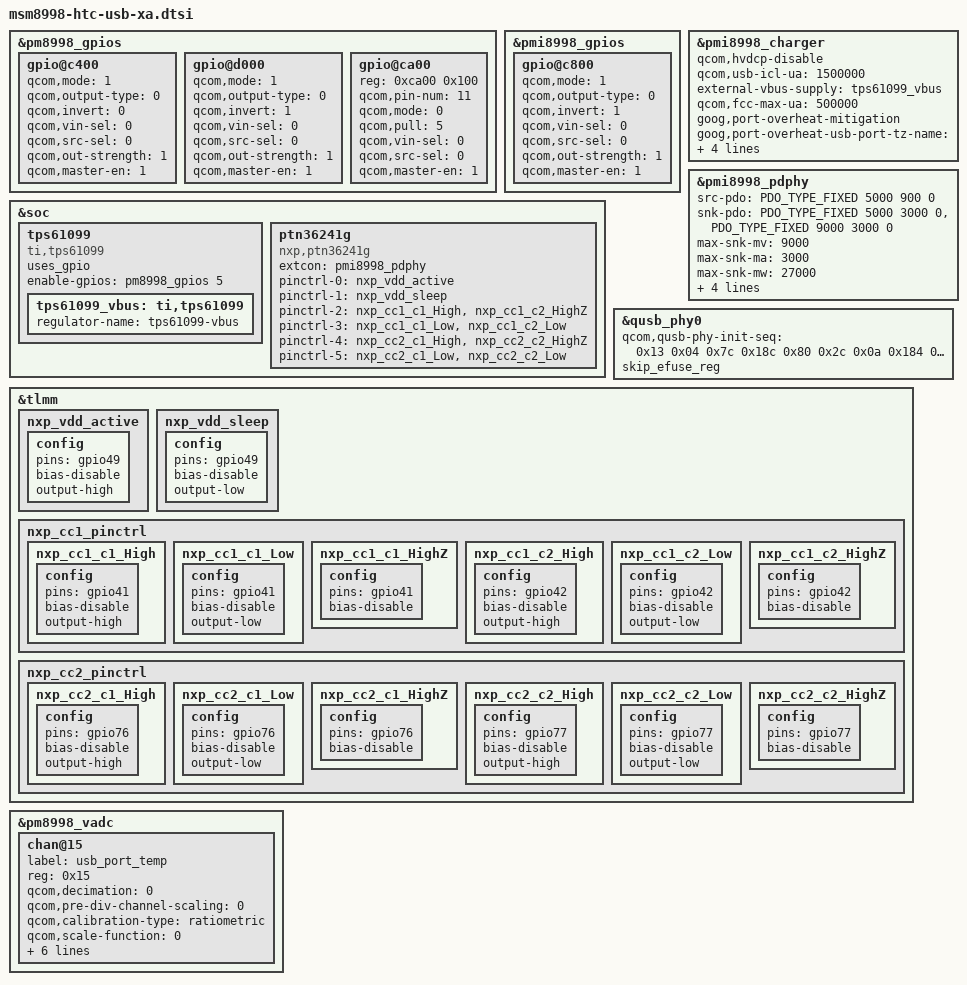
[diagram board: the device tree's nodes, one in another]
/*
 * Copyright (c) 2017, The Linux Foundation. All rights reserved.
 *
 * This program is free software; you can redistribute it and/or modify
 * it under the terms of the GNU General Public License version 2 and
 * only version 2 as published by the Free Software Foundation.
 *
 * This program is distributed in the hope that it will be useful,
 * but WITHOUT ANY WARRANTY; without even the implied warranty of
 * MERCHANTABILITY or FITNESS FOR A PARTICULAR PURPOSE.  See the
 * GNU General Public License for more details.
 */

#include <dt-bindings/usb/typec.h>

&pm8998_gpios {
	gpio@c400 { /* GPIO 5 - V_OTG_5V_EN_AP */
		qcom,mode = <1>;
		qcom,output-type = <0>;
		qcom,invert = <0>;
		qcom,vin-sel = <0>;
		qcom,src-sel = <0>;
		qcom,out-strength = <1>;
		qcom,master-en = <1>;
		status = "okay";
	};

	gpio@d000 { /* GPIO 17 - V_OTG_VOUT_SET */
		qcom,mode = <1>;
		qcom,output-type = <0>;
		qcom,invert = <1>;
		qcom,vin-sel = <0>;
		qcom,src-sel = <0>;
		qcom,out-strength = <1>;
		qcom,master-en = <1>;
		status = "okay";
	};
};

&pmi8998_gpios {
	gpio@c800 { /* GPIO 9 - V_LED_3V3_EN - shared power for Re-drive */
		qcom,mode = <1>;
		qcom,output-type = <0>;
		qcom,invert = <1>;
		qcom,vin-sel = <0>;
		qcom,src-sel = <0>;
		qcom,out-strength = <1>;
		qcom,master-en = <1>;
		status = "okay";
	};
};

&soc {
	tps61099 {
		compatible = "ti,tps61099";
		uses_gpio;

		enable-gpios = <&pm8998_gpios 5 0>;

		tps61099_vbus: ti,tps61099 {
			regulator-name = "tps61099-vbus";
		};
	};
};

&pmi8998_charger {
	qcom,hvdcp-disable;		/* disable HVDCP */
	qcom,usb-icl-ua = <1500000>;
	external-vbus-supply = <&tps61099_vbus>;
	/*
	 * a conservative value used to limit charge current in case the
	 * charging module is not loaded. The charging module would change
	 * the value to allow faster charging.
	 */
	qcom,fcc-max-ua = <500000>;
};

&pmi8998_pdphy {
	src-pdo = <PDO_TYPE_FIXED 5000 900 0>;	/* 5V-0.9A */
	snk-pdo = <PDO_TYPE_FIXED 5000 3000 0>,	/* 5V-3A */
		  <PDO_TYPE_FIXED 9000 3000 0>;	/* 9V-3A */
	max-snk-mv = <9000>;
	max-snk-ma = <3000>;
	max-snk-mw = <27000>;
	op-snk-mw = <7600>;
	port-type = <TYPEC_PORT_DRP>;
	default-role = <TYPEC_SINK>;
	try-role-hw;
};

&qusb_phy0 {
	qcom,qusb-phy-init-seq =
			/* <value reg_offset> */
				<0x13 0x04 /* analog_controls_two */
				0x7c 0x18c /* pll_clock_inverter */
				0x80 0x2c /* pll_cmode */
				0x0a 0x184 /* pll_lock_delay */
				0xf5 0x23c /* tune1 */
				0x0b 0x240 /* tune2 */
				0xe4 0x248 /* tune4 */
				0x19 0xb4>; /* digital_timers_two */
	skip_efuse_reg;
};

&soc {
	ptn36241g {
		compatible = "nxp,ptn36241g";
		extcon = <&pmi8998_pdphy>;

		pinctrl-names = "nxp_vdd_active", "nxp_vdd_sleep",
				"nxp_cc1_active-HH", "nxp_cc1_sleep-LL",
				"nxp_cc2_active-HH", "nxp_cc2_sleep-LL";
		/*USBSS_SW_1V8_EN - on*/
		pinctrl-0 = <&nxp_vdd_active>;
		/*USBSS_SW_1V8_EN - off*/
		pinctrl-1 = <&nxp_vdd_sleep>;
		/*nxp_cc1_active-HH*/
		pinctrl-2 = <&nxp_cc1_c1_High &nxp_cc1_c2_HighZ>;
		/*nxp_cc1_sleep-LL*/
		pinctrl-3 = <&nxp_cc1_c1_Low &nxp_cc1_c2_Low>;
		/*nxp_cc2_active-HH*/
		pinctrl-4 = <&nxp_cc2_c1_High &nxp_cc2_c2_HighZ>;
		/*nxp_cc2_sleep-LL*/
		pinctrl-5 = <&nxp_cc2_c1_Low &nxp_cc2_c2_Low>;
	};
};

&tlmm {
	nxp_vdd_active: nxp_vdd_active {
		config {
			pins = "gpio49";
			bias-disable;
			output-high;
		};
	};

	nxp_vdd_sleep: nxp_vdd_sleep {
		config {
			pins = "gpio49";
			bias-disable;
			output-low;
		};
	};

	nxp_cc1_pinctrl {
		nxp_cc1_c1_High: nxp_cc1_c1_High {
			config {
				pins = "gpio41";
				bias-disable;
				output-high;
			};
		};

		nxp_cc1_c1_Low: nxp_cc1_c1_Low {
			config {
				pins = "gpio41";
				bias-disable;
				output-low;
			};
		};

		nxp_cc1_c1_HighZ: nxp_cc1_c1_HighZ {
			config {
				pins = "gpio41";
				bias-disable;
			};
		};

		nxp_cc1_c2_High: nxp_cc1_c2_High {
			config {
				pins = "gpio42";
				bias-disable;
				output-high;
			};
		};

		nxp_cc1_c2_Low: nxp_cc1_c2_Low {
			config {
				pins = "gpio42";
				bias-disable;
				output-low;
			};
		};

		nxp_cc1_c2_HighZ: nxp_cc1_c2_HighZ {
			config {
				pins = "gpio42";
				bias-disable;
			};
		};
	};

	nxp_cc2_pinctrl {
		nxp_cc2_c1_High: nxp_cc2_c1_High {
			config {
				pins = "gpio76";
				bias-disable;
				output-high;
			};
		};

		nxp_cc2_c1_Low: nxp_cc2_c1_Low {
			config {
				pins = "gpio76";
				bias-disable;
				output-low;
			};
		};

		nxp_cc2_c1_HighZ: nxp_cc2_c1_HighZ {
			config {
				pins = "gpio76";
				bias-disable;
			};
		};

		nxp_cc2_c2_High: nxp_cc2_c2_High {
			config {
				pins = "gpio77";
				bias-disable;
				output-high;
			};
		};

		nxp_cc2_c2_Low: nxp_cc2_c2_Low {
			config {
				pins = "gpio77";
				bias-disable;
				output-low;
			};
		};

		nxp_cc2_c2_HighZ: nxp_cc2_c2_HighZ {
			config {
				pins = "gpio77";
				bias-disable;
			};
		};
	};
};

/* usb port temperature adc */
&pm8998_gpios {
	gpio@ca00 {
		reg = <0xca00 0x100>;
		qcom,pin-num = <11>;
		status = "okay";
		qcom,mode = <0>;
		qcom,pull = <5>;
		qcom,vin-sel = <0>;
		qcom,src-sel = <0>;
		qcom,master-en = <1>;
	};
};

&pm8998_vadc {
	chan@15 {
		label = "usb_port_temp";
		reg = <0x15>;
		qcom,decimation = <0>;
		qcom,pre-div-channel-scaling = <0>;
		qcom,calibration-type = "ratiometric";
		qcom,scale-function = <0>;
		qcom,hw-settle-time = <1>;	/* 100us hardware settle time */
		qcom,fast-avg-setup = <2>;	/* average 4 samples */
		qcom,cal-val = <0>;
		qcom,vadc-thermal-node;
		goog,custom-map =
				<(-200) 1668000
				(-190) 1659000
				(-180) 1651000
				(-170) 1641000
				(-160) 1632000
				(-150) 1622000
				(-140) 1611000
				(-130) 1600000
				(-120) 1589000
				(-110) 1577000
				(-100) 1565000
				(-90) 1552000
				(-80) 1539000
				(-70) 1525000
				(-60) 1511000
				(-50) 1496000
				(-40) 1481000
				(-30) 1466000
				(-20) 1449000
				(-10) 1433000
				0 1416000
				10 1398000
				20 1381000
				30 1362000
				40 1344000
				50 1325000
				60 1305000
				70 1286000
				80 1266000
				90 1245000
				100 1225000
				110 1204000
				120 1183000
				130 1161000
				140 1140000
				150 1118000
				160 1096000
				170 1075000
				180 1053000
				190 1031000
				200 1009000
				210 987000
				220 965000
				230 943000
				240 922000
				250 900000
				260 879000
				270 857000
				280 836000
				290 815000
				300 795000
				310 774000
				320 754000
				330 734000
				340 715000
				350 695000
				360 677000
				370 658000
				380 640000
				390 622000
				400 604000
				410 587000
				420 570000
				430 554000
				440 537000
				450 522000
				460 506000
				470 491000
				480 477000
				490 462000
				500 449000
				510 435000
				520 422000
				530 409000
				540 397000
				550 385000
				560 373000
				570 361000
				580 350000
				590 339000
				600 329000
				610 319000
				620 309000
				630 300000
				640 290000
				650 281000
				660 273000
				670 264000
				680 256000
				690 248000
				700 241000
				710 233000
				720 226000
				730 219000
				740 212000
				750 206000
				760 200000
				770 193000
				780 188000
				790 182000
				800 176000
				810 171000
				820 166000
				830 161000
				840 156000
				850 151000
				860 147000
				870 142000
				880 138000
				890 134000
				900 130000
				910 126000
				920 123000
				930 119000
				940 116000
				950 112000
				960 109000
				970 106000
				980 103000
				990 100000
				1000 97000
				1010 94000
				1020 91000
				1030 89000
				1040 86000
				1050 84000
				1060 82000
				1070 79000
				1080 77000
				1090 75000
				1100 73000
				1110 71000
				1120 69000
				1130 67000
				1140 65000
				1150 64000
				1160 62000
				1170 60000
				1180 59000
				1190 57000
				1200 56000
				1210 54000
				1220 53000
				1230 51000
				1240 50000
				1250 49000>;
	};
};

&pmi8998_charger {
	goog,port-overheat-mitigation;
	goog,port-overheat-usb-port-tz-name = "usb_port_temp";
	goog,port-overheat-begin-temp = <600>;
	goog,port-overheat-end-temp = <500>;
	goog,port-overheat-work-interval = <1000>;
};
